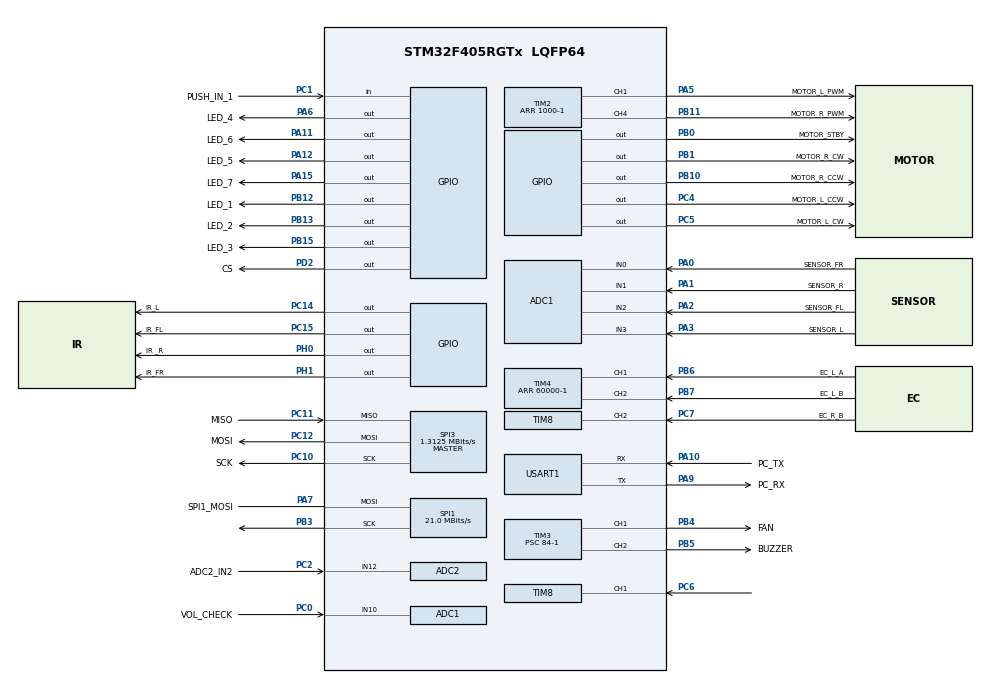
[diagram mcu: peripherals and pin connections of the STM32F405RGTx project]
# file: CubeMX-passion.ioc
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ADC1.Channel-0\#ChannelRegularConversion=ADC_CHANNEL_1
ADC1.Channel-1\#ChannelRegularConversion=ADC_CHANNEL_3
ADC1.Channel-2\#ChannelRegularConversion=ADC_CHANNEL_0
ADC1.Channel-3\#ChannelRegularConversion=ADC_CHANNEL_2
ADC1.Channel-4\#ChannelRegularConversion=ADC_CHANNEL_10
ADC1.ClockPrescaler=ADC_CLOCK_SYNC_PCLK_DIV2
ADC1.DMAContinuousRequests=ENABLE
ADC1.EOCSelection=ADC_EOC_SEQ_CONV
ADC1.NbrOfConversion=5
ADC1.NbrOfConversionFlag=1
ADC1.Rank-0\#ChannelRegularConversion=1
ADC1.Rank-1\#ChannelRegularConversion=2
ADC1.Rank-2\#ChannelRegularConversion=3
ADC1.Rank-3\#ChannelRegularConversion=4
ADC1.Rank-4\#ChannelRegularConversion=5
ADC1.SamplingTime-0\#ChannelRegularConversion=ADC_SAMPLETIME_15CYCLES
ADC1.SamplingTime-1\#ChannelRegularConversion=ADC_SAMPLETIME_15CYCLES
ADC1.SamplingTime-2\#ChannelRegularConversion=ADC_SAMPLETIME_15CYCLES
ADC1.SamplingTime-3\#ChannelRegularConversion=ADC_SAMPLETIME_15CYCLES
ADC1.SamplingTime-4\#ChannelRegularConversion=ADC_SAMPLETIME_15CYCLES
ADC1.ScanConvMode=ENABLE
ADC1.master=1
ADC2.Channel-0\#ChannelRegularConversion=ADC_CHANNEL_12
ADC2.DMAContinuousRequests=ENABLE
ADC2.EOCSelection=ADC_EOC_SEQ_CONV
ADC2.NbrOfConversionFlag=1
ADC2.Rank-0\#ChannelRegularConversion=1
ADC2.SamplingTime-0\#ChannelRegularConversion=ADC_SAMPLETIME_15CYCLES
ADC2.ScanConvMode=ENABLE
Dma.ADC1.0.Direction=DMA_PERIPH_TO_MEMORY
Dma.ADC1.0.FIFOMode=DMA_FIFOMODE_DISABLE
Dma.ADC1.0.Instance=DMA2_Stream0
Dma.ADC1.0.MemDataAlignment=DMA_MDATAALIGN_HALFWORD
Dma.ADC1.0.MemInc=DMA_MINC_ENABLE
Dma.ADC1.0.Mode=DMA_CIRCULAR
Dma.ADC1.0.PeriphDataAlignment=DMA_PDATAALIGN_HALFWORD
Dma.ADC1.0.PeriphInc=DMA_PINC_DISABLE
Dma.ADC1.0.Priority=DMA_PRIORITY_LOW
Dma.ADC2.1.Direction=DMA_PERIPH_TO_MEMORY
Dma.ADC2.1.FIFOMode=DMA_FIFOMODE_DISABLE
Dma.ADC2.1.Instance=DMA2_Stream2
Dma.ADC2.1.MemDataAlignment=DMA_MDATAALIGN_HALFWORD
Dma.ADC2.1.MemInc=DMA_MINC_ENABLE
Dma.ADC2.1.Mode=DMA_CIRCULAR
Dma.ADC2.1.PeriphDataAlignment=DMA_PDATAALIGN_HALFWORD
Dma.ADC2.1.PeriphInc=DMA_PINC_DISABLE
Dma.ADC2.1.Priority=DMA_PRIORITY_LOW
Dma.Request0=ADC1
Dma.Request1=ADC2
Mcu.Family=STM32F4
Mcu.Name=STM32F405RGTx
Mcu.Package=LQFP64
NVIC.DMA2_Stream0_IRQn=true\:0\:0\:false\:false\:true\:false\:true\:true
NVIC.DMA2_Stream2_IRQn=true\:0\:0\:false\:false\:true\:false\:true\:true
NVIC.PriorityGroup=NVIC_PRIORITYGROUP_4
NVIC.TIM1_BRK_TIM9_IRQn=true\:0\:0\:false\:false\:true\:true\:true\:true
PA0-WKUP.GPIO_Label=SENSOR_FR
PA0-WKUP.Signal=ADCx_IN0
PA1.GPIO_Label=SENSOR_R
PA1.Signal=ADCx_IN1
PA10.GPIO_Label=PC_TX
PA10.Mode=Asynchronous
PA10.Signal=USART1_RX
PA11.GPIO_Label=LED_6
PA11.Signal=GPIO_Output
PA12.GPIO_Label=LED_5
PA12.Signal=GPIO_Output
PA13.GPIO_Label=SWDIO
PA13.Signal=SYS_JTMS-SWDIO
PA14.GPIO_Label=SWCL
PA14.Signal=SYS_JTCK-SWCLK
PA15.GPIO_Label=LED_7
PA15.Signal=GPIO_Output
PA2.GPIO_Label=SENSOR_FL
PA2.Signal=ADCx_IN2
PA3.GPIO_Label=SENSOR_L
PA3.Signal=ADCx_IN3
PA5.GPIO_Label=MOTOR_L_PWM
PA5.Signal=S_TIM2_CH1_ETR
PA6.GPIO_Label=LED_4
PA6.Signal=GPIO_Output
PA7.GPIO_Label=SPI1_MOSI
PA7.Mode=Simplex_Bidirectional_Master
PA7.Signal=SPI1_MOSI
PA8.GPIO_Label=SCL
PA8.Signal=I2C3_SCL
PA9.GPIO_Label=PC_RX
PA9.Mode=Asynchronous
PA9.Signal=USART1_TX
PB0.GPIO_Label=MOTOR_STBY
PB0.Signal=GPIO_Output
PB1.GPIO_Label=MOTOR_R_CW
PB1.Signal=GPIO_Output
PB10.GPIO_Label=MOTOR_R_CCW
PB10.Signal=GPIO_Output
PB11.GPIO_Label=MOTOR_R_PWM
PB11.Signal=S_TIM2_CH4
PB12.GPIO_Label=LED_1
PB12.Signal=GPIO_Output
PB13.GPIO_Label=LED_2
PB13.Signal=GPIO_Output
PB15.GPIO_Label=LED_3
PB15.Signal=GPIO_Output
PB3.Mode=Simplex_Bidirectional_Master
PB3.Signal=SPI1_SCK
PB4.GPIO_Label=FAN
PB4.Signal=S_TIM3_CH1
PB5.GPIO_Label=BUZZER
PB5.Signal=S_TIM3_CH2
PB6.GPIO_Label=EC_L_A
PB6.Signal=S_TIM4_CH1
PB7.GPIO_Label=EC_L_B
PB7.Signal=S_TIM4_CH2
PC0.GPIO_Label=VOL_CHECK
PC0.Signal=ADCx_IN10
PC1.GPIO_Label=PUSH_IN_1
PC1.Signal=GPIO_Input
PC10.GPIO_Label=SCK
PC10.Mode=Full_Duplex_Master
PC10.Signal=SPI3_SCK
PC11.GPIO_Label=MISO
PC11.Mode=Full_Duplex_Master
PC11.Signal=SPI3_MISO
PC12.GPIO_Label=MOSI
PC12.Mode=Full_Duplex_Master
PC12.Signal=SPI3_MOSI
PC14-OSC32_IN.GPIO_Label=IR_L
PC14-OSC32_IN.Signal=GPIO_Output
PC15-OSC32_OUT.GPIO_Label=IR_FL
PC15-OSC32_OUT.Signal=GPIO_Output
PC2.GPIO_Label=ADC2_IN2
PC2.Signal=ADCx_IN12
PC4.GPIO_Label=MOTOR_L_CCW
PC4.Signal=GPIO_Output
PC5.GPIO_Label=MOTOR_L_CW
PC5.Signal=GPIO_Output
PC6.Signal=S_TIM8_CH1
PC7.GPIO_Label=EC_R_B
PC7.Signal=S_TIM8_CH2
PC9.GPIO_Label=SDA
PC9.Signal=I2C3_SDA
PD2.GPIO_Label=CS
PD2.Signal=GPIO_Output
PH0-OSC_IN.GPIO_Label=IR _R
PH0-OSC_IN.Signal=GPIO_Output
PH1-OSC_OUT.GPIO_Label=IR_FR
PH1-OSC_OUT.Signal=GPIO_Output
ProjectManager.HeapSize=0x200
ProjectManager.StackSize=0x400
ProjectManager.TargetToolchain=Makefile
RCC.48MHZClocksFreq_Value=84000000
RCC.AHBFreq_Value=168000000
RCC.APB1CLKDivider=RCC_HCLK_DIV4
RCC.APB1Freq_Value=42000000
RCC.APB1TimFreq_Value=84000000
RCC.APB2CLKDivider=RCC_HCLK_DIV4
RCC.APB2Freq_Value=42000000
RCC.APB2TimFreq_Value=84000000
RCC.CortexFreq_Value=168000000
RCC.HCLKFreq_Value=168000000
RCC.HSE_VALUE=25000000
RCC.HSI_VALUE=16000000
RCC.LSE_VALUE=32768
RCC.PLLM=8
RCC.PLLN=168
RCC.SYSCLKFreq_VALUE=168000000
RCC.SYSCLKSource=RCC_SYSCLKSOURCE_PLLCLK
RCC.VCOOutputFreq_Value=336000000
SH.ADCx_IN0.0=ADC1_IN0,IN0
SH.ADCx_IN1.0=ADC1_IN1,IN1
SH.ADCx_IN10.0=ADC1_IN10,IN10
SH.ADCx_IN12.0=ADC2_IN12,IN12
SH.ADCx_IN2.0=ADC1_IN2,IN2
SH.ADCx_IN3.0=ADC1_IN3,IN3
SH.S_TIM2_CH1_ETR.0=TIM2_CH1,PWM Generation1 CH1
SH.S_TIM2_CH4.0=TIM2_CH4,PWM Generation4 CH4
SH.S_TIM3_CH1.0=TIM3_CH1,PWM Generation1 CH1
SH.S_TIM3_CH2.0=TIM3_CH2,PWM Generation2 CH2
SH.S_TIM4_CH1.0=TIM4_CH1,Encoder_Interface
SH.S_TIM4_CH2.0=TIM4_CH2,Encoder_Interface
SH.S_TIM8_CH1.0=TIM8_CH1,Encoder_Interface
SH.S_TIM8_CH2.0=TIM8_CH2,Encoder_Interface
SPI1.CalculateBaudRate=21.0 MBits/s
SPI1.Direction=SPI_DIRECTION_1LINE
SPI1.Mode=SPI_MODE_MASTER
SPI1.VirtualType=VM_MASTER
SPI3.BaudRatePrescaler=SPI_BAUDRATEPRESCALER_32
SPI3.CalculateBaudRate=1.3125 MBits/s
SPI3.Direction=SPI_DIRECTION_2LINES
SPI3.Mode=SPI_MODE_MASTER
SPI3.VirtualType=VM_MASTER
TIM1.Channel-Output\ Compare1\ No\ Output=TIM_CHANNEL_1
TIM1.Period=1000
TIM1.Prescaler=84-1
TIM2.Channel-PWM\ Generation1\ CH1=TIM_CHANNEL_1
TIM2.Channel-PWM\ Generation4\ CH4=TIM_CHANNEL_4
TIM2.Period=1000-1
TIM3.Channel-PWM\ Generation1\ CH1=TIM_CHANNEL_1
TIM3.Channel-PWM\ Generation2\ CH2=TIM_CHANNEL_2
TIM3.Period=1000-1
TIM3.Prescaler=84-1
TIM4.Channel-Output\ Compare3\ No\ Output=TIM_CHANNEL_3
TIM4.EncoderMode=TIM_ENCODERMODE_TI12
TIM4.Period=60000-1
TIM5.Period=1000-1
TIM5.Prescaler=84-1
TIM8.EncoderMode=TIM_ENCODERMODE_TI12
TIM8.Period=60000-1
TIM8.TIM_MasterOutputTrigger=TIM_TRGO_ENABLE
USART1.VirtualMode=VM_ASYNC
VP_TIM1_VS_ClockSourceINT.Mode=Internal
VP_TIM1_VS_no_output1.Mode=Output Compare1 No Output
VP_TIM2_VS_ClockSourceINT.Mode=Internal
VP_TIM3_VS_ClockSourceINT.Mode=Internal
VP_TIM4_VS_no_output3.Mode=Output Compare3 No Output
VP_TIM5_VS_ClockSourceINT.Mode=Internal
board=custom

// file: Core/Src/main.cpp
/* USER CODE BEGIN Header */
/**
  ******************************************************************************
  * @file           : main.c
  * @brief          : Main program body
  ******************************************************************************
  * @attention
  *
  * Copyright (c) 2024 STMicroelectronics.
  * All rights reserved.
  *
  * This software is licensed under terms that can be found in the LICENSE file
  * in the root directory of this software component.
  * If no LICENSE file comes with this software, it is provided AS-IS.
  *
  ******************************************************************************
  */
/* USER CODE END Header */

/* USER CODE BEGIN Includes */
#include <iostream>
#include <memory>

#include "peripheral.h"
#include "stdout.h"
#include "objects.hpp"
#include "interrupt.hpp"
#include "drive.hpp"
#include "regulator.hpp"
#include "accel_designer.h"
#include "flags.hpp"
#include "search.hpp"
#include "consts.hpp"
/* USER CODE END Includes */

int main()
{

  HAL_Init();

  SystemClock_Config();

  MX_GPIO_Init();
  MX_DMA_Init();
  MX_ADC1_Init();
  MX_USART1_UART_Init();
  MX_TIM2_Init();
  MX_TIM3_Init();
  MX_TIM4_Init();
  MX_TIM8_Init();
  MX_SPI1_Init();
  MX_TIM5_Init();
  MX_SPI3_Init();
  MX_TIM1_Init();
  MX_ADC2_Init();

  //hello_world
  printf("hello_c\n");
  std::cout << "hello_c++" << std::endl;
  std::cout << "C++ : " << __cplusplus << "\n";
  //hello_world
  /*----------------------------------起動シーケンス開始----------------------------*/
  /*-------------------------------------INIT-------------------------------------*/
  //objectsのインスタンス化(本来，objectsはstaticなクラスであるが，ここではインスタンス化している)
  std::unique_ptr<Objects> objects = std::make_unique<Objects>();
  std::cout << "objects_Instance" << std::endl;
  //objectsの初期化
  //すべてのstaticなクラスのインスタンス化を行う．
  objects->Init();
  std::cout << "objects_Init" << std::endl;
  //objectsを利用した初期化を行う．
  //designのインスタンス化
  std::unique_ptr<ctrl::Design> design = std::make_unique<ctrl::Design>(Objects::accel_designer_);
  std::cout << "design_Instance" << std::endl;
  //driveのインスタンス化
  std::unique_ptr<drive::Core> core =
  std::make_unique<drive::Core>(Objects::motor_reg_,Objects::imu_,Objects::encoder_,Objects::md_,
  design,Objects::traj_l90_,Objects::traj_r90_,Objects::wall_);
  std::cout << "drive_Instance" << std::endl;
  //Searchのインスタンス化
 std::unique_ptr<maze::Search> search =
 std::make_unique<maze::Search>(Objects::wall_,Objects::wait_,core,Objects::encoder_,Objects::eeprom_,
 consts::software::GOAL_X,consts::software::GOAL_Y);
  /*----------初期化シーケンス実行------------*/

  Objects::buzzer_->Play(500,50);

  Objects::imu_->Init();
  Objects::encoder_->Init();
  Objects::pxstr_->Init();
  Objects::wall_->Init();

  /*motorの確認*/
  Objects::md_->On();
  Objects::md_->Dir(state::MOTOR::LEFT,state::MOTOR::FWD);
  Objects::md_->Dir(state::MOTOR::RIGHT,state::MOTOR::FWD);
  Objects::md_->Duty(0,0);
  Objects::buzzer_->Play(500,50,1);
  Objects::md_->Duty(5,5);
  Objects::md_->Start();
  Objects::wait_->Ms(100);
  Objects::buzzer_->Play(500,50,1);
  Objects::md_->Duty(0,0);
  Objects::md_->ShortBrake();
  /*motorの確認*/

  /*offsetを一旦とる*/
  Objects::wall_->GetOffset();
  Objects::encoder_->GetOffset();
  Objects::encoder_->Start();
  Objects::imu_->GetOffset();
  /*offsetを一旦とる*/
  /*------------初期化シーケンス終了------------*/
  //interruputの初期化を行う．
  peripheral::IT::Init(&htim5);
  /*-------------------------------------INIT-------------------------------------*/
  peripheral::IT::Start();
  /*encoderの確認*/
  core->CurveAD(90,0,100);
  while(Flag::Check(DRIVE_START)){
    if(Objects::encoder_->get_val_ref()->dist[static_cast<int>(state::Motion::DIR::C)] > 110){
      Objects::buzzer_->Play(1000,500);
      for(int i = 0;i < 10;i++){
        Objects::led_->On();
        Objects::wait_->Ms(50);
        Objects::led_->Off();
        Objects::wait_->Ms(50);
      }
      break;
    }
  };
  core->Stop();
  /*encoderの確認*/
  for(int i = 0; i < 4; i++){
    Objects::buzzer_->Play(500 + i * 50, 50);
    Objects::wait_->Ms(5);
  }

  Objects::buzzer_->Play(500,50);
  Objects::wait_->Ms(100);
  Objects::buzzer_->Play(500,2000);//2秒//正しい位置に置く猶予

  Objects::wall_->GetOffset();
  Objects::encoder_->GetOffset();
  Objects::encoder_->Start();
  Objects::imu_->GetOffset();

  Objects::buzzer_->Play(500,50);
  Objects::wait_->Ms(100);
  Objects::buzzer_->Play(500,50);
  /*-------------------------------------起動シーケンス終了-------------------------------------*/

  // core->Straight(270,0,0);
  // while(true);
  // core->Slalom_L90(300);
  //   while(Flag::Check(DRIVE_START)){}
  // core->Slalom_R90(300);
  //   while(Flag::Check(DRIVE_START)){}
  // core->SpinTurn();
  //   while(Flag::Check(DRIVE_START)){}

  // Objects::led_->On();
  // core->Stop();
  // while(true);
  search->SearchInit();
  Flag::Set(FWALL_CTRL);
  //Flag::Reset(FWALL_CTRL);

  uint8_t mode = 0;

  while (1) {
        mode = Objects::mode_sw_->ModeSelect(mode);

        switch (mode) {
        case 0:

            break;

        case 1:

            printf("mode 1.\n");

            /*OFFSET*/
            Objects::buzzer_->Play(500,50);
            Objects::wait_->Ms(100);
            Objects::buzzer_->Play(500,2000);//2秒//正しい位置に置く猶予

            Objects::wall_->GetOffset();
            Objects::encoder_->GetOffset();
            Objects::encoder_->Start();
            Objects::imu_->GetOffset();

            Objects::buzzer_->Play(500,50);
            Objects::wait_->Ms(100);
            Objects::buzzer_->Play(500,50);

            Objects::imu_->ResetAngle();
            Objects::encoder_->ResetDist();

            //----フラグの初期化----
            Flag::ResetAll();
            //----マップデータ初期化----
            //search->SearchInit();

            std::cout << "searchB" << std::endl;
            //二次走行フラグをクリア
            Flag::Reset(SCND);
            search->set_goal(consts::software::GOAL_X,consts::software::GOAL_Y);//ゴール座標設定
            core->Ketsu();
            //機体が安定するまで
            Objects::wait_->Ms(300);
            //壁制御用のオフセットを取得
            Objects::imu_->GetOffset();
            Objects::wall_->GetOffset();
            //サーチBする
            search->SearchB();
            //なんか待つ
            Objects::wait_->Ms(500);
            //ゴール座標を設定する
            search->set_goal(consts::software::GOAL_X,consts::software::GOAL_Y);

            break;

        case 2:
            //スラロームの右90度
            printf("mode 2.\n");

            /*OFFSET*/
            Objects::buzzer_->Play(500,50);
            Objects::wait_->Ms(100);
            Objects::buzzer_->Play(500,2000);//2秒//正しい位置に置く猶予

            Objects::wall_->GetOffset();
            Objects::encoder_->GetOffset();
            Objects::encoder_->Start();
            Objects::imu_->GetOffset();

            Objects::buzzer_->Play(500,50);
            Objects::wait_->Ms(100);
            Objects::buzzer_->Play(500,50);

            Objects::imu_->ResetAngle();
            Objects::encoder_->ResetDist();
            /*OFFSET*/

            core->Straight(180,0,0);
            core->Stop();

            break;

        case 3:

            printf("mode 3.\n");

            /*OFFSET*/
            Objects::buzzer_->Play(500,50);
            Objects::wait_->Ms(100);
            Objects::buzzer_->Play(500,2000);//2秒//正しい位置に置く猶予

            Objects::wall_->GetOffset();
            Objects::encoder_->GetOffset();
            Objects::encoder_->Start();
            Objects::imu_->GetOffset();

            Objects::buzzer_->Play(500,50);
            Objects::wait_->Ms(100);
            Objects::buzzer_->Play(500,50);

            Objects::imu_->ResetAngle();
            Objects::encoder_->ResetDist();
            /*OFFSET*/
            while(true){
            Objects::wait_->Ms(200);
            std::cout << Objects::wall_->get_raw_ref()->dir[static_cast<int>(state::Wall::DIR::L)] << "\t";
            std::cout << Objects::wall_->get_raw_ref()->dir[static_cast<int>(state::Wall::DIR::FL)] << "\t";
            std::cout << Objects::wall_->get_raw_ref()->dir[static_cast<int>(state::Wall::DIR::FR)] << "\t";
            std::cout << Objects::wall_->get_raw_ref()->dir[static_cast<int>(state::Wall::DIR::R)] << std::endl;
            }

            break;

        case 4:

            printf("mode 4.\n");

            Objects::buzzer_->Play(500,50);
            Objects::wait_->Ms(100);
            Objects::buzzer_->Play(500,2000);//2秒//正しい位置に置く猶予

            Objects::wall_->GetOffset();
            Objects::encoder_->GetOffset();
            Objects::encoder_->Start();
            Objects::imu_->GetOffset();

            Objects::buzzer_->Play(500,50);
            Objects::wait_->Ms(100);
            Objects::buzzer_->Play(500,50);
            /*OFFSET*/

            core->Straight(180,0,0);
            core->Stop();

            break;
        case 5:
            /*OFFSET*/
            Objects::buzzer_->Play(500,50);
            Objects::wait_->Ms(100);
            Objects::buzzer_->Play(500,2000);//2秒//正しい位置に置く猶予

            Objects::wall_->GetOffset();
            Objects::encoder_->GetOffset();
            Objects::encoder_->Start();
            Objects::imu_->GetOffset();

            Objects::buzzer_->Play(500,50);
            Objects::wait_->Ms(100);
            Objects::buzzer_->Play(500,50);

            Objects::imu_->ResetAngle();
            Objects::encoder_->ResetDist();
            /*OFFSET*/

            //----フラグの初期化----
            Flag::ResetAll();
            //----マップデータ初期化----
            search->SearchInit();

            std::cout << "searchB" << std::endl;
            //二次走行フラグをクリア
            Flag::Reset(SCND);
            search->set_goal(consts::software::GOAL_X,consts::software::GOAL_Y);//ゴール座標設定
            core->Ketsu();
            //機体が安定するまで
            Objects::wait_->Ms(300);
            //壁制御用のオフセットを取得
            Objects::imu_->GetOffset();
            Objects::wall_->GetOffset();
            //サーチBする
            search->SearchB();
            //なんか待つ
            Objects::wait_->Ms(500);
            Objects::led_->On();
            Objects::wait_->Ms(500);
            Objects::led_->Off();
            //ゴール座標をスタート地点にしてもっかいsearchB
            search->set_goal(0,0);
            core->Ketsu();
            //機体が安定するまで
            Objects::wait_->Ms(300);

            search->SearchB();
            //おかえり

            //ゴール座標を設定する
            search->set_goal(consts::software::GOAL_X,consts::software::GOAL_Y);

            for(uint8_t i = 0;i < 8 ;i++){

            //----フラグの初期化----
            Flag::ResetAll();
            Flag::Set(SCND);
            search->set_goal(consts::software::GOAL_X,consts::software::GOAL_Y);//ゴール座標設定
            search->set_spd(500);
            core->Ketsu();
            //機体が安定するまで
            Objects::wait_->Ms(300);
            //サーチBする
            search->SearchB();
            //なんか待つ
            Objects::wait_->Ms(500);
            //ゴール座標を設定する
            search->set_goal(0,0);
            core->Ketsu();
            //機体が安定するまで
            Objects::wait_->Ms(300);
            search->SearchB();
            //ゴール座標を設定する
            search->set_goal(consts::software::GOAL_X,consts::software::GOAL_Y);

            }

            break;

        case 6:

            printf("Mode 6\n");

            //二次走行だけ
            /*OFFSET*/
            Objects::buzzer_->Play(500,50);
            Objects::wait_->Ms(100);
            Objects::buzzer_->Play(500,2000);//2秒//正しい位置に置く猶予

            Objects::wall_->GetOffset();
            Objects::encoder_->GetOffset();
            Objects::encoder_->Start();
            Objects::imu_->GetOffset();

            Objects::buzzer_->Play(500,50);
            Objects::wait_->Ms(100);
            Objects::buzzer_->Play(500,50);

            Objects::imu_->ResetAngle();
            Objects::encoder_->ResetDist();

            //----フラグの初期化----
            Flag::ResetAll();
            Flag::Set(SCND);
            search->set_goal(consts::software::GOAL_X,consts::software::GOAL_Y);//ゴール座標設定
            search->set_spd(550);
            core->Ketsu();
            //機体が安定するまで
            Objects::wait_->Ms(300);
            //壁制御用のオフセットを取得
            Objects::imu_->GetOffset();
            Objects::wall_->GetOffset();
            //サーチBする
            search->SearchB();
            //なんか待つ
            Objects::wait_->Ms(500);
            break;

        case 7:

            printf("Mode 7\n");

            printf("Mode 6\n");

            //二次走行だけ
            /*OFFSET*/
            Objects::buzzer_->Play(500,50);
            Objects::wait_->Ms(100);
            Objects::buzzer_->Play(500,2000);//2秒//正しい位置に置く猶予

            Objects::wall_->GetOffset();
            Objects::encoder_->GetOffset();
            Objects::encoder_->Start();
            Objects::imu_->GetOffset();

            Objects::buzzer_->Play(500,50);
            Objects::wait_->Ms(100);
            Objects::buzzer_->Play(500,50);

            Objects::imu_->ResetAngle();
            Objects::encoder_->ResetDist();

            //----フラグの初期化----
            Flag::ResetAll();
            Flag::Set(SCND);
            search->set_goal(consts::software::GOAL_X,consts::software::GOAL_Y);//ゴール座標設定
            search->set_spd(700);
            core->Ketsu();
            //機体が安定するまで
            Objects::wait_->Ms(300);
            //壁制御用のオフセットを取得
            Objects::imu_->GetOffset();
            Objects::wall_->GetOffset();
            //サーチBする
            search->SearchB();
            //なんか待つ
            Objects::wait_->Ms(500);
            break;

            break;

            case 8:

            printf("Mode 8\n");
            Objects::buzzer_->Play(500,50);
            Objects::wait_->Ms(100);
            Objects::buzzer_->Play(500,2000);//2秒//正しい位置に置く猶予

            Objects::wall_->GetOffset();
            Objects::encoder_->GetOffset();
            Objects::encoder_->Start();
            Objects::imu_->GetOffset();

            Objects::buzzer_->Play(500,50);
            Objects::wait_->Ms(100);
            Objects::buzzer_->Play(500,50);
            /*OFFSET*/
            core->Straight(consts::software::HALF_BLOCK,consts::software::SPD_SEARCH,0);  //半区画分減速しながら走行し停止
            core->Stop();

            HAL_Delay(1000);  //スタートでは***2秒以上***停止しなくてはならない
            //rotate_180();
            core->SpinTurn();  //180度回転
            break;
        }
    }

  /*========================searchB====================================================*/
  // std::cout << "searchB" << std::endl;
  // //二次走行フラグをクリア
  // Flag::Reset(SCND);
  // search->set_goal(consts::software::GOAL_X,consts::software::GOAL_Y);//ゴール座標設定
  // core->Ketsu();
  // //機体が安定するまで
  // Objects::wait_->Ms(100);
  // //壁制御用のオフセットを取得
  // Objects::imu_->GetOffset();
  // Objects::wall_->GetOffset();
  // //サーチBする
  // search->SearchB();
  // //なんか待つ
  // Objects::wait_->Ms(500);
  // //ゴール座標を設定する
  // search->set_goal(consts::software::GOAL_X,consts::software::GOAL_Y);
  /*========================searchB====================================================*/

  // core->SpinTurn();
  // while(Flag::Check(DRIVE_START)){}

  // Objects::led_->On();
  //core->Ketsu();
  //core->Stop();
  // Objects::md_->Off();
  // Objects::led_->Off();

  // core->CurveAD(180,0,500);
  // while(Flag::Check(DRIVE_START)){}
  // Objects::buzzer_->Start(500,5);
  // Objects::led_->On();

  // core->CurveAD(40,500,500);
  // while(Flag::Check(DRIVE_START)){}
  // core->Slalom_R90(500);
  // while(Flag::Check(DRIVE_START)){}
  // core->CurveAD(72,500,500);
  // while(Flag::Check(DRIVE_START)){}

  // core->CurveAD(50,500,500);
  // while(Flag::Check(DRIVE_START)){}
  // core->Slalom_L90(500);
  // while(Flag::Check(DRIVE_START)){}
  // core->CurveAD(40,500,500);

  // Objects::buzzer_->Start(500,50);
  /*Flag::Check(DRIVE_START)*/
  // while(true){
  //   Objects::wait_->Ms(5);
  //   // std::cout << "t_cnt_ : " << Objects::motor_reg_->t_cnt_ << "\t";
  //   //std::cout << "r_dist:" << Objects::motor_reg_->r_->dist[static_cast<int>(state::Motion::DIR::C)] << "\t";
  //   // std::cout << "s_.dq.th : " << Objects::motor_reg_->s_.dq.th*consts::physics::RAD2DEG << "\t";
  //   // std::cout << "s.q.th : " << Objects::motor_reg_->s_.q.th*consts::physics::RAD2DEG << "\t";
  //   // std::cout << "r_v" << Objects::traj_r90_->getVelocity() << "\t";
  //   // std::cout << "end_t " << Objects::traj_r90_->getTimeCurve() << "\t";

  //   // std::cout << "raw_sensor_l : " << Objects::wall_->get_raw_ref()->dir[static_cast<int>(state::Wall::DIR::L)] << "\t";
  //   // std::cout << "raw_sensor_fl : " << Objects::wall_->get_raw_ref()->dir[static_cast<int>(state::Wall::DIR::FL)] << "\t";
  //   // std::cout << "raw_sensor_fr : " << Objects::wall_->get_raw_ref()->dir[static_cast<int>(state::Wall::DIR::FR)] << "\t";
  //   // std::cout << "raw_sensor_r : " << Objects::wall_->get_raw_ref()->dir[static_cast<int>(state::Wall::DIR::R)] << "\t";

  //   //std::cout << "l_v" << Objects::traj_l90_->getVelocity() << "\t";
  //   //std::cout << "end_t " << Objects::traj_l90_->getTimeCurve() << "\t";
  //   // std::cout << "v : " << Objects::motor_reg_->r_->spd[static_cast<int>(state::Motion::DIR::C)] << "\t";
  //   // std::cout << "l_encoder:" << Objects::encoder_->get_raw_ref()->spd[static_cast<int>(state::Motion::DIR::L)] << "\t";
  //   // std::cout << "r_encoder:" << Objects::encoder_->get_raw_ref()->spd[static_cast<int>(state::Motion::DIR::R)]<< "\t";
  //   std::cout << "l_encoder:" << Objects::encoder_->get_val_ref()->dist[static_cast<int>(state::Motion::DIR::L)] << "\t";
  //   std::cout << "r_encoder:" << Objects::encoder_->get_val_ref()->dist[static_cast<int>(state::Motion::DIR::R)]<< "\t";
  //   //std::cout << "dist:" << Objects::encoder_->get_val_ref()->dist[static_cast<int>(state::Motion::DIR::C)] << "\t";
  //   // std::cout << "DRIVE_START : " << Flag::Check(DRIVE_START) << "\t";
  //   // std::cout << "DRIVE_STRAIGHT : " << Flag::Check(DRIVE_STRAIGHT) << "\t";
  //   // std::cout << "DRIVE_SLALOM_L90 : " << Flag::Check(DRIVE_SLALOM_L90) << std::endl;
  //   // std::cout << "imu_omega:" << Objects::imu_->get_val_ref()->omega[static_cast<int>(state::Motion::AXIS::Z)] << "\t";
  //   // std::cout << "omega_r" << Objects::accel_designer_->v(Objects::motor_reg_->t_cnt_) << "\t";
  //   // std::cout << "imu_angle: " << Objects::imu_->get_val_ref()->angle[static_cast<int>(state::Motion::AXIS::Z)] << "\t";
  //   //std::cout << "x_t_end : " << Objects::accel_designer_->x(Objects::accel_designer_->t_end()) + 5<< std::endl;
  //   std::cout << std::endl;
  // }
  // Objects::led_->Off();
  // Objects::buzzer_->Start(500,50);
  //Objects::md_->ShortBrake();
  // core->Stop();
  // Objects::wait_->Ms(100);
  //Objects::led_->Off();
  // Objects::buzzer_->Stop();
  // Objects::buzzer_->Start(500,10 );
  //Objects::md_->ShortBrake();
  // Objects::wait_->Ms(100);
  // Objects::buzzer_->Stop();
  /* USER CODE END 3 */
}

void Error_Handler(void)
{
  __disable_irq();
  while (1)
  {
  }
}
